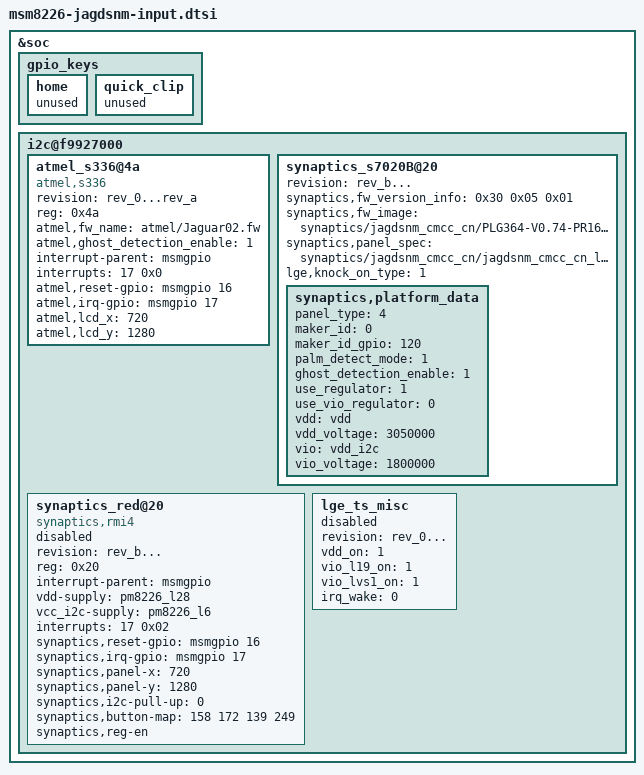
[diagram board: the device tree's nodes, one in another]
/* Copyright (c) 2013, LGE Electronics. All rights reserved.
 *
 * This program is free software; you can redistribute it and/or modify
 * it under the terms of the GNU General Public License version 2 and
 * only version 2 as published by the Free Software Foundation.
 *
 * This program is distributed in the hope that it will be useful,
 * but WITHOUT ANY WARRANTY; without even the implied warranty of
 * MERCHANTABILITY or FITNESS FOR A PARTICULAR PURPOSE.  See the
 * GNU General Public License for more details.
 */

&soc {
        gpio_keys {
	    home {
		unused;
	    };
	    quick_clip {
		unused;
	    };
	};
	i2c@f9927000 { /* BLSP1 QUP5 */
		atmel_s336@4a {
			compatible = "atmel,s336";
			revision = "rev_0...rev_a";
			status = "ok";
			reg = <0x4a>;
			atmel,fw_name = "atmel/Jaguar02.fw";
			atmel,ghost_detection_enable = <1>;
			interrupt-parent = <&msmgpio>;
			interrupts = <17 0x0>;
			atmel,reset-gpio = <&msmgpio 16 0x00>;
			atmel,irq-gpio = <&msmgpio 17 0x00>;
			atmel,lcd_x = <720>;
			atmel,lcd_y = <1280>;
		};
		synaptics_s7020B@20 {
		    revision = "rev_b...";
		    status = "ok";
		    synaptics,fw_version_info = <0x30 0x05 0x01>;
		    synaptics,fw_image = "synaptics/jagdsnm_cmcc_cn/PLG364-V0.74-PR1666447-DS4.3.5.1.16_3005014A.img";
		    synaptics,panel_spec = "synaptics/jagdsnm_cmcc_cn/jagdsnm_cmcc_cn_limit.txt";
		    lge,knock_on_type = <1>;
		    synaptics,platform_data{
			/* firmware image depends on this value, temporarily used */
			/* 0: No image(default), 1: W3DS(TIM BR)(PLG312_T001), 2: W3S(VDF)(PLG311_T001), 3:X3, 4:W5DS, 5:W5S ... */
			panel_type = <4>;
			/*maker_id  disable(0), enable(1)*/
			maker_id = <0>;
			maker_id_gpio = <120>;
			palm_detect_mode = <1>;
			ghost_detection_enable = <1>;
			/*power*/
			use_regulator = <1>;
			use_vio_regulator = <0>;
			vdd = "vdd";
			vdd_voltage = <3050000>;
			vio = "vdd_i2c";
			vio_voltage = <1800000>;
		    };
		};

		synaptics_red@20 {
		    compatible = "synaptics,rmi4";
		    status = "disable";
		    revision = "rev_b...";
		    reg = <0x20>;
		    interrupt-parent = <&msmgpio>;
		    vdd-supply = <&pm8226_l28>;
		    vcc_i2c-supply = <&pm8226_l6>;
		    interrupts = <17 0x02>;
		    synaptics,reset-gpio = <&msmgpio 16 0x00>;
		    synaptics,irq-gpio = <&msmgpio 17 0x02>;
		    synaptics,panel-x = <720>;
		    synaptics,panel-y = <1280>;
		    synaptics,i2c-pull-up = <0>;
		    synaptics,button-map = <158 172 139 249>;
		    synaptics,reg-en;
		};
		lge_ts_misc {
			revision = "rev_0...";
			vdd_on = <1>;
			vio_l19_on = <1>;
			vio_lvs1_on = <1>;
			irq_wake = <0>;
			status ="disable";
		};
	};
};
